# sysexc register map
Vendor: Texas Instruments
Peripheral module from a debugger description file (folder sc4cc231e6pm).
Registers are 32-bit, read-only, no defined reset value unless marked. A register's access mark holds for its fields unless they carry their own. Offsets are as the file gives them; lines under a group give offsets from that group; [hi:lo] are bit positions; {n}, {i} and the like mark numbered series; 'fields as' and 'values as' point back to an identical list; <NAME> marks a mode.

## SYSEXC — System Exception Module register addresses
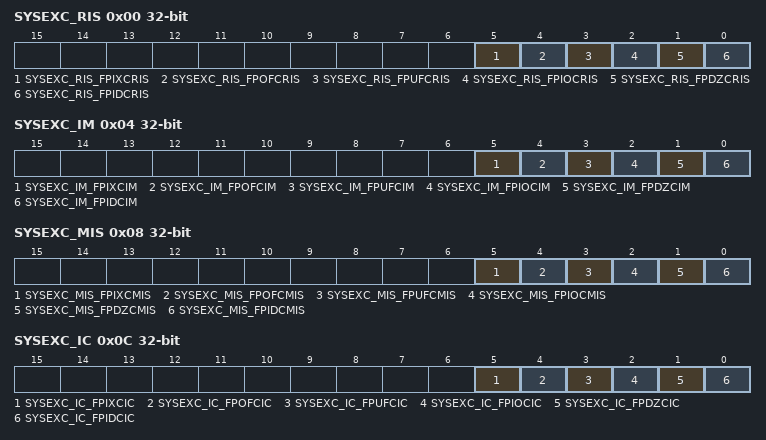
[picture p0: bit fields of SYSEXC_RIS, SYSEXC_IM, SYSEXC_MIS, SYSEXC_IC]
0x00 SYSEXC_RIS — System Exception Raw Interrupt Status
  [5] SYSEXC_RIS_FPIXCRIS — Floating-Point Inexact Exception Raw Interrupt Status
  [4] SYSEXC_RIS_FPOFCRIS — Floating-Point Overflow Exception Raw Interrupt Status
  [3] SYSEXC_RIS_FPUFCRIS — Floating-Point Underflow Exception Raw Interrupt Status
  [2] SYSEXC_RIS_FPIOCRIS — Floating-Point Invalid Operation Raw Interrupt Status
  [1] SYSEXC_RIS_FPDZCRIS — Floating-Point Divide By 0 Exception Raw Interrupt Status
  [0] SYSEXC_RIS_FPIDCRIS — Floating-Point Input Denormal Exception Raw Interrupt Status
0x04 SYSEXC_IM rw — System Exception Interrupt Mask
  [5] SYSEXC_IM_FPIXCIM — Floating-Point Inexact Exception Interrupt Mask
  [4] SYSEXC_IM_FPOFCIM — Floating-Point Overflow Exception Interrupt Mask
  [3] SYSEXC_IM_FPUFCIM — Floating-Point Underflow Exception Interrupt Mask
  [2] SYSEXC_IM_FPIOCIM — Floating-Point Invalid Operation Interrupt Mask
  [1] SYSEXC_IM_FPDZCIM — Floating-Point Divide By 0 Exception Interrupt Mask
  [0] SYSEXC_IM_FPIDCIM — Floating-Point Input Denormal Exception Interrupt Mask
0x08 SYSEXC_MIS — System Exception Masked Interrupt Status
  [5] SYSEXC_MIS_FPIXCMIS — Floating-Point Inexact Exception Masked Interrupt Status
  [4] SYSEXC_MIS_FPOFCMIS — Floating-Point Overflow Exception Masked Interrupt Status
  [3] SYSEXC_MIS_FPUFCMIS — Floating-Point Underflow Exception Masked Interrupt Status
  [2] SYSEXC_MIS_FPIOCMIS — Floating-Point Invalid Operation Masked Interrupt Status
  [1] SYSEXC_MIS_FPDZCMIS — Floating-Point Divide By 0 Exception Masked Interrupt Status
  [0] SYSEXC_MIS_FPIDCMIS — Floating-Point Input Denormal Exception Masked Interrupt Status
0x0C SYSEXC_IC wo — System Exception Interrupt Clear
  [5] SYSEXC_IC_FPIXCIC — Floating-Point Inexact Exception Interrupt Clear
  [4] SYSEXC_IC_FPOFCIC — Floating-Point Overflow Exception Interrupt Clear
  [3] SYSEXC_IC_FPUFCIC — Floating-Point Underflow Exception Interrupt Clear
  [2] SYSEXC_IC_FPIOCIC — Floating-Point Invalid Operation Interrupt Clear
  [1] SYSEXC_IC_FPDZCIC — Floating-Point Divide By 0 Exception Interrupt Clear
  [0] SYSEXC_IC_FPIDCIC — Floating-Point Input Denormal Exception Interrupt Clear
